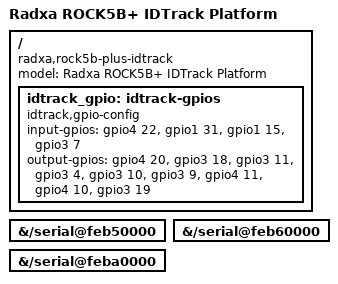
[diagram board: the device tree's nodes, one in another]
/dts-v1/;

/include/ "rk3588-rock5b-plus-base.dts"

/ {
    model = "Radxa ROCK5B+ IDTrack Platform";
    compatible = "radxa,rock5b-plus-idtrack", "radxa,rock5b-plus", "rockchip,rk3588";

    idtrack_gpio: idtrack-gpios {
        compatible = "idtrack,gpio-config";

        input-gpios =
            <&gpio4 22 0>,   /* gpio150 */
            <&gpio1 31 0>,   /* gpio63 */
            <&gpio1 15 0>,   /* gpio47 */
            <&gpio3 7 0>;    /* gpio103 */

        output-gpios =
            <&gpio4 20 0>,   /* gpio148 */
            <&gpio3 18 0>,   /* gpio114 */
            <&gpio3 11 0>,   /* gpio107 */
            <&gpio3 4 0>,    /* gpio100 */
            <&gpio3 10 0>,   /* gpio106 */
            <&gpio3 9 0>,    /* gpio105 */
            <&gpio4 11 0>,   /* gpio139 */
            <&gpio4 10 0>,   /* gpio138 */
            <&gpio3 19 0>;   /* gpio115 */
    };
};

&{/serial@feb50000} {
    status = "okay";
};

&{/serial@feb60000} {
    status = "okay";
};

&{/serial@feba0000} {
    status = "okay";
};
